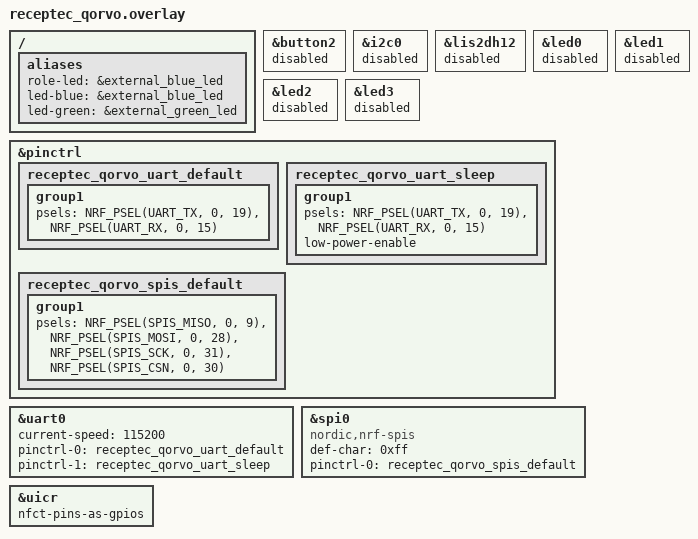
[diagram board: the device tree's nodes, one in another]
/* SPDX-License-Identifier: Apache-2.0 */

#include <zephyr/dt-bindings/pinctrl/nrf-pinctrl.h>

/* Custom carrier: DWM3001C radio module, Raspberry Pi 5 host. */

/ {
	aliases {
		role-led = &external_blue_led;
		led-blue = &external_blue_led;
		led-green = &external_green_led;
	};
};

/* DWM3001CDK carrier parts not populated on RECEPTEC-Qorvo. */
&button2 { status = "disabled"; };
&i2c0 { status = "disabled"; };
&lis2dh12 { status = "disabled"; };
&led0 { status = "disabled"; };
&led1 { status = "disabled"; };
&led2 { status = "disabled"; };
&led3 { status = "disabled"; };

/* UART console and Raspberry Pi header: TX=P0.19, RX=P0.15. */
&pinctrl {
	receptec_qorvo_uart_default: receptec_qorvo_uart_default {
		group1 {
			psels = <NRF_PSEL(UART_TX, 0, 19)>,
				<NRF_PSEL(UART_RX, 0, 15)>;
		};
	};
	receptec_qorvo_uart_sleep: receptec_qorvo_uart_sleep {
		group1 {
			psels = <NRF_PSEL(UART_TX, 0, 19)>,
				<NRF_PSEL(UART_RX, 0, 15)>;
			low-power-enable;
		};
	};
};

&uart0 {
	status = "okay";
	current-speed = <115200>;
	pinctrl-0 = <&receptec_qorvo_uart_default>;
	pinctrl-1 = <&receptec_qorvo_uart_sleep>;
	pinctrl-names = "default", "sleep";
};

/* Raspberry Pi SPI master interface from sheet 3 of the hardware package. */
&pinctrl {
	receptec_qorvo_spis_default: receptec_qorvo_spis_default {
		group1 {
			psels = <NRF_PSEL(SPIS_MISO, 0, 9)>,
				<NRF_PSEL(SPIS_MOSI, 0, 28)>,
				<NRF_PSEL(SPIS_SCK, 0, 31)>,
				<NRF_PSEL(SPIS_CSN, 0, 30)>;
		};
	};
};

&spi0 {
	compatible = "nordic,nrf-spis";
	status = "okay";
	def-char = <0xff>;
	pinctrl-0 = <&receptec_qorvo_spis_default>;
	pinctrl-names = "default";
};

&uicr {
	nfct-pins-as-gpios;
};
